# PIC32MX675F512L device description
Architecture: MIPS; Family: PIC32MX; Series: PIC32MX
Registers are 32-bit, read-write, no defined reset value unless marked. A register's access mark holds for its fields unless they carry their own. Offsets are from the block's base; [hi:lo] are bit positions; 'fields as' and 'values as' point back to an identical list.

## SPI
Instances: SPI 0x1f8057f4 in periph0
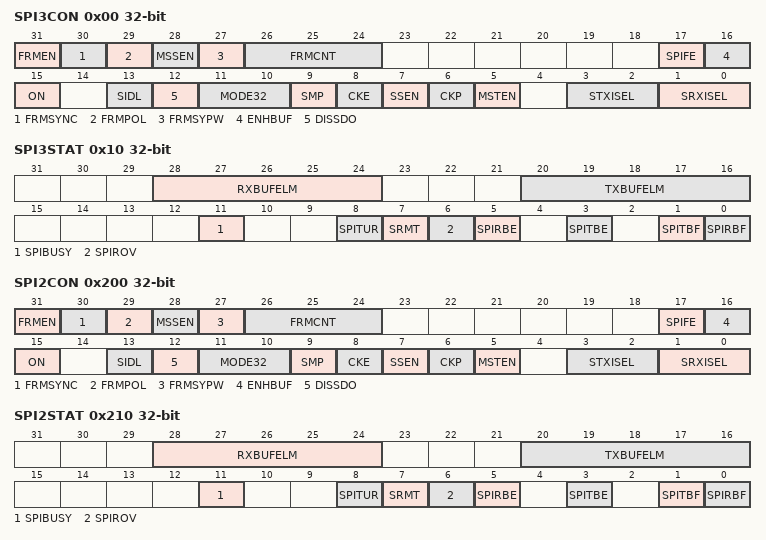
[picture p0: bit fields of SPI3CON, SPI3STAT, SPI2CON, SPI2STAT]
0x00 SPI3CON — SPI Control Register
  [31] FRMEN — Framed SPI Support bit
    1=Framed SPI support is enabled (SSx pin used as FSYNC input/output); 0=Framed SPI support is disabled
  [30] FRMSYNC — Frame Sync Pulse Direction Control on SSx pin bit (Framed SPI mode only)
    1=Frame sync pulse input (Slave mode); 0=Frame sync pulse output (Master mode)
  [29] FRMPOL — Frame Sync Polarity bit (Framed SPI mode only)
    1=Frame pulse is active-high; 0=Frame pulse is active-low
  [28] MSSEN — Master Mode Slave Select Enable bit
    1=Slave select SPI support enabled. The SS pin is automatically driven during transmission in Master mode. Polarity is determined by the FRMPOL bit.; 0=Slave select SPI support is disabled
  [27] FRMSYPW — Frame Sync Pulse Width bit
    1=Frame sync pulse is one character wide; 0=Frame sync pulse is one clock wide
  [26:24] FRMCNT — Frame Sync Pulse Counter bits. Controls the number of data characters transmitted per pulse. This bit is only valid in FRAMED_SYNC mode.
    5=Generate a frame sync pulse on every 32 data characters; 4=Generate a frame sync pulse on every 16 data characters; 3=Generate a frame sync pulse on every 8 data characters; 2=Generate a frame sync pulse on every 4 data characters; 1=Generate a frame sync pulse on every 2 data characters; 0=Generate a frame sync pulse on every data character
  [17] SPIFE — Frame Sync Pulse Edge Select bit
    1=Frame synchronization pulse coincides with the first bit clock; 0=Frame synchronization pulse precedes the first bit clock
  [16] ENHBUF — Enhanced Buffer Enable bit
    1=Enhanced Buffer mode is enabled; 0=Enhanced Buffer mode is disabled
  [15] ON — SPI Peripheral On bit
    1=SPI Peripheral is enabled; 0=SPI Peripheral is disabled
  [13] SIDL — Stop in Idle Mode bit
    1=Discontinue operation when CPU enters in Idle mode; 0=Continue operation in Idle mode
  [12] DISSDO — Disable SDOx pin bit
    1=SDOx pin is not used by the module. Pin is controlled by associated PORT register; 0=SDOx pin is controlled by the module
  [11:10] MODE32 — 32/16-Bit Communication Select bits
    3=(AUDEN=1) 24-bit Data, 32-bit FIFO, 32-bit Channel/64-bit Frame / (AUDEN=0) 32-bit communication; 2=(AUDEN=1) 32-bit Data, 32-bit FIFO, 32-bit Channel/64-bit Frame / (AUDEN=0) 32-bit communication; 1=(AUDEN=1) 16-bit Data, 16-bit FIFO, 32-bit Channel/64-bit Frame / (AUDEN=0) 16-bit communication; 0=(AUDEN=1) 16-bit Data, 16-bit FIFO, 16-bit Channel/32-bit Frame / (AUDEN=0) 8-bit communication
  [9] SMP — SPI Data Input Sample Phase bit (master mode only)
    1=(Master mode) Input data sampled at end of data output time / (Slave mode) value is ignored; 0=(Master mode) Input data sampled at middle of data output time / (Slave mode) value is ignored
  [8] CKE — SPI Clock Edge Select bit
    1=Serial output data changes on transition from active clock state to Idle clock state (see CKP bit); 0=Serial output data changes on transition from Idle clock state to active clock state (see CKP bit)
  [7] SSEN — Slave Select Enable bit
    1=SSx pin used for Slave mode; 0=SSx pin not used for Slave mode
  [6] CKP — Clock Polarity Select bit
    1=Idle state for clock is a high level; active state is a low level; 0=Idle state for clock is a low level; active state is a high level
  [5] MSTEN — Master Mode Enable bit
    1=Master mode; 0=Slave mode
  [3:2] STXISEL — SPI Transmit Buffer Empty Interrupt Mode bits
    3=Interrupt is generated when the buffer is not full (has one or more empty elements); 2=Interrupt is generated when the buffer is empty by one-half or more; 1=Interrupt is generated when the buffer is completely empty; 0=Interrupt is generated when the last transfer is shifted out of SPISR and transmit operations are complete
  [1:0] SRXISEL — SPI Receive Buffer Full Interrupt Mode bits
    3=Interrupt is generated when the buffer is full; 2=Interrupt is generated when the buffer is full by one-half or more; 1=Interrupt is generated when the buffer is not empty; 0=Interrupt is generated when the last word in the receive buffer is read (i.e. buffer is empty)
0x10 SPI3STAT ro
  [28:24] RXBUFELM
  [20:16] TXBUFELM
  [11] SPIBUSY — SPI Activity Status bit
    1=SPI peripheral is currently busy with some transactions; 0=SPI peripheral is currently idle
  [8] SPITUR — Transmit Under Run bit
    1=Transmit buffer has encountered an underrun condition; 0=Transmit buffer has no underrun condition
  [7] SRMT — Shift Register Empty bit (valid only when ENHBUF = 1)
    1=When SPI module shift register is empty; 0=When SPI module shift register is not empty
  [6] SPIROV — Receive Overflow Flag bit
    1=A new data is completely received and discarded. The user software has not read the previous data in the SPIxBUF register.; 0=No overflow has occurred
  [5] SPIRBE — RX FIFO Empty bit (valid only when ENHBUF = 1)
    1=RX FIFO is empty (CRPTR = SWPTR); 0=RX FIFO is not empty (CRPTR != SWPTR)
  [3] SPITBE — SPI Transmit Buffer Empty Status bit
    1=Transmit buffer SPIxTXB is empty; 0=Transmit buffer SPIxTXB is not empty
  [1] SPITBF — SPI Transmit Buffer Full Status bit
    1=Transmit not yet started SPITXB is full; 0=Transmit buffer is not full
  [0] SPIRBF — SPI Receive Buffer Full Status bit
    1=Receive buffer SPIxRXB is full; 0=Receive buffer SPIxRXB is not full
0x20 SPI3BUF
0x30 SPI3BRG
  [8:0] SPI3BRG
0x200 SPI2CON — SPI Control Register
  fields as SPI3CON
0x210 SPI2STAT ro
  fields as SPI3STAT
0x220 SPI2BUF
0x230 SPI2BRG
  [8:0] SPI2BRG
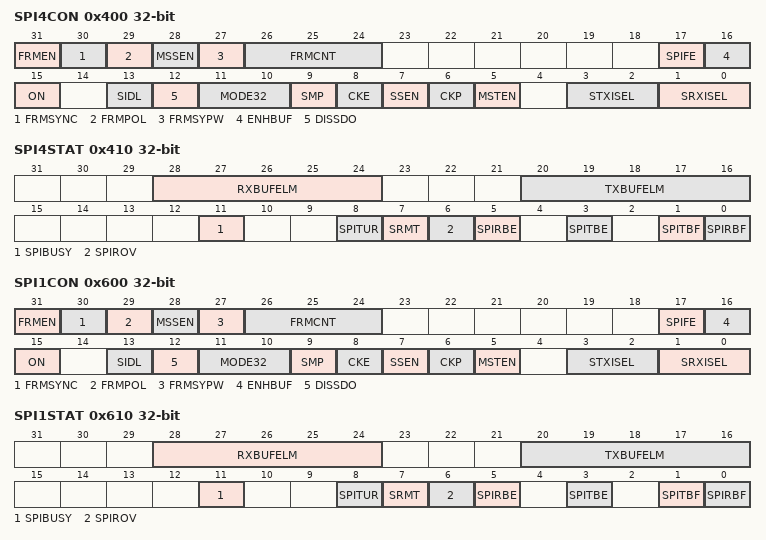
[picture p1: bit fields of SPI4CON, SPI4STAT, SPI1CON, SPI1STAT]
0x400 SPI4CON — SPI Control Register
  fields as SPI3CON
0x410 SPI4STAT ro
  fields as SPI3STAT
0x420 SPI4BUF
0x430 SPI4BRG
  [8:0] SPI4BRG
0x600 SPI1CON — SPI Control Register
  fields as SPI3CON
0x610 SPI1STAT ro
  fields as SPI3STAT
0x620 SPI1BUF
0x630 SPI1BRG
  [8:0] SPI1BRG

## Notices in the file
Copyright (c) 2019 Microchip Technology Inc.
SPDX-License-Identifier: Apache-2.0
Licensed under the Apache License, Version 2.0 (the "License");
you may not use this file except in compliance with the License.
You may obtain a copy of the License at
http://www.apache.org/licenses/LICENSE-2.0
Unless required by applicable law or agreed to in writing, software
distributed under the License is distributed on an "AS IS" BASIS,
WITHOUT WARRANTIES OR CONDITIONS OF ANY KIND, either express or implied.
See the License for the specific language governing permissions and
limitations under the License.
